VERSION "HIPBNYYYYYYYYYYYYYYYYYYYYYYYYYYYYYYYYYYYYY/4/%%%/4/'%**4YYY///"

NS_ :

BS_:

BU_: CUSTOM_BMS

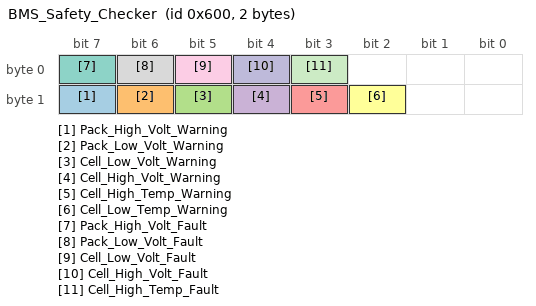
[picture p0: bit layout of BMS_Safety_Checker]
BO_ 1536 BMS_Safety_Checker: 2 [CUSTOM_BMS]
 SG_ Pack_High_Volt_Warning : 15|1@1+ (1,0) [0|1] "" Vector__XXX
 SG_ Pack_Low_Volt_Warning : 14|1@1+ (1,0) [0|1] "" Vector__XXX
 SG_ Cell_Low_Volt_Warning : 13|1@1+ (1,0) [0|1] "" Vector__XXX
 SG_ Cell_High_Volt_Warning : 12|1@1+ (1,0) [0|1] "" Vector__XXX
 SG_ Cell_High_Temp_Warning : 11|1@1+ (1,0) [0|1] "" Vector__XXX
 SG_ Cell_Low_Temp_Warning : 10|1@1+ (1,0) [0|1] "" Vector__XXX
 SG_ Pack_High_Volt_Fault : 7|1@1+ (1,0) [0|1] "" Vector__XXX
 SG_ Pack_Low_Volt_Fault : 6|1@1+ (1,0) [0|1] "" Vector__XXX
 SG_ Cell_Low_Volt_Fault : 5|1@1+ (1,0) [0|1] "" Vector__XXX
 SG_ Cell_High_Volt_Fault : 4|1@1+ (1,0) [0|1] "" Vector__XXX
 SG_ Cell_High_Temp_Fault : 3|1@1+ (1,0) [0|1] "" Vector__XXX
